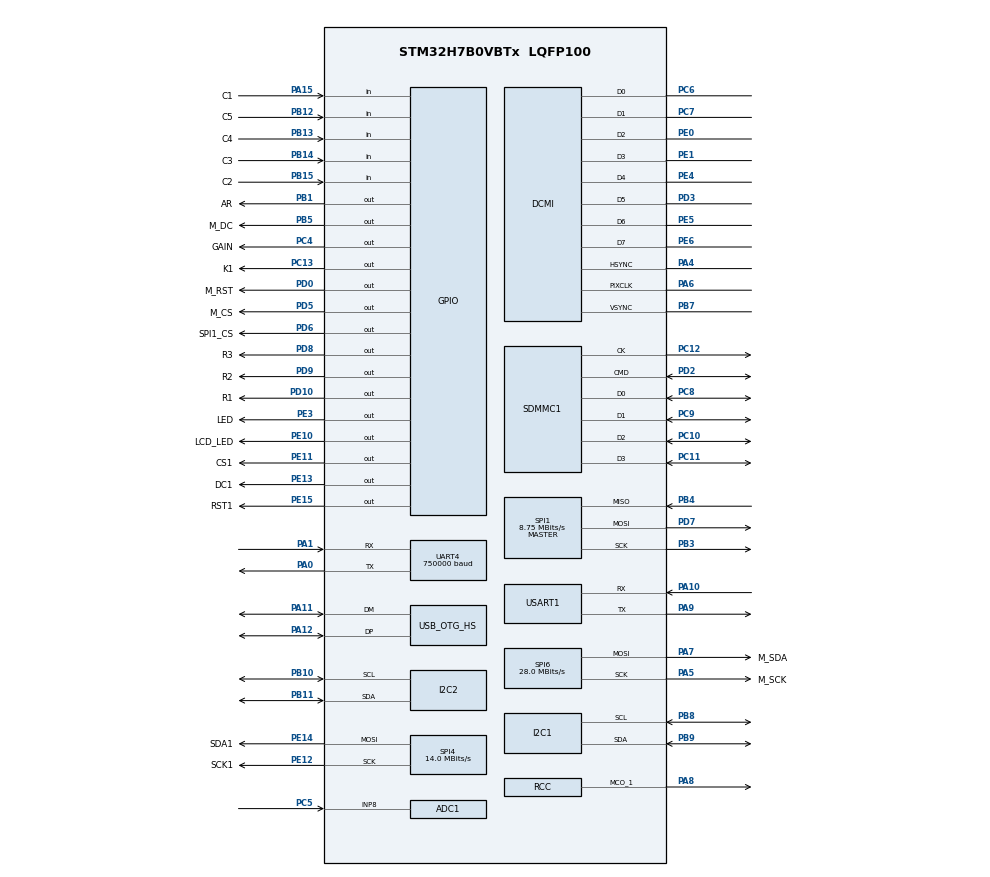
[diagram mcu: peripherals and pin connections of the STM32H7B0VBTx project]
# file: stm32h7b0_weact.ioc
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ADC1.Channel-0\#ChannelRegularConversion=ADC_CHANNEL_8
ADC1.ClockPrescaler=ADC_CLOCK_ASYNC_DIV8
ADC1.NbrOfConversionFlag=1
ADC1.OffsetNumber-0\#ChannelRegularConversion=ADC_OFFSET_NONE
ADC1.OffsetSignedSaturation-0\#ChannelRegularConversion=DISABLE
ADC1.Rank-0\#ChannelRegularConversion=1
ADC1.SamplingTime-0\#ChannelRegularConversion=ADC_SAMPLETIME_1CYCLE_5
ADC1.master=1
ADC2.Channel-0\#ChannelRegularConversion=ADC_CHANNEL_8
ADC2.ClockPrescaler=ADC_CLOCK_ASYNC_DIV8
ADC2.ContinuousConvMode=DISABLE
ADC2.ConversionDataManagement=ADC_CONVERSIONDATA_DMA_CIRCULAR
ADC2.DiscontinuousConvMode=ENABLE
ADC2.ExternalTrigConv=ADC_EXTERNALTRIG_T15_TRGO
ADC2.NbrOfConversionFlag=1
ADC2.OffsetNumber-0\#ChannelRegularConversion=ADC_OFFSET_NONE
ADC2.OffsetSignedSaturation-0\#ChannelRegularConversion=DISABLE
ADC2.Rank-0\#ChannelRegularConversion=1
ADC2.SamplingTime-0\#ChannelRegularConversion=ADC_SAMPLETIME_1CYCLE_5
CORTEX_M7.CPU_DCache=Enabled
CORTEX_M7.CPU_ICache=Enabled
Dma.ADC2.1.Direction=DMA_PERIPH_TO_MEMORY
Dma.ADC2.1.EventEnable=DISABLE
Dma.ADC2.1.FIFOMode=DMA_FIFOMODE_DISABLE
Dma.ADC2.1.Instance=DMA1_Stream0
Dma.ADC2.1.MemDataAlignment=DMA_MDATAALIGN_HALFWORD
Dma.ADC2.1.MemInc=DMA_MINC_ENABLE
Dma.ADC2.1.Mode=DMA_CIRCULAR
Dma.ADC2.1.PeriphDataAlignment=DMA_PDATAALIGN_HALFWORD
Dma.ADC2.1.PeriphInc=DMA_PINC_DISABLE
Dma.ADC2.1.Polarity=HAL_DMAMUX_REQ_GEN_RISING
Dma.ADC2.1.Priority=DMA_PRIORITY_LOW
Dma.ADC2.1.RequestNumber=1
Dma.ADC2.1.SignalID=NONE
Dma.ADC2.1.SyncEnable=DISABLE
Dma.ADC2.1.SyncPolarity=HAL_DMAMUX_SYNC_NO_EVENT
Dma.ADC2.1.SyncRequestNumber=1
Dma.ADC2.1.SyncSignalID=NONE
Dma.MEMTOMEM.2.Direction=DMA_MEMORY_TO_MEMORY
Dma.MEMTOMEM.2.EventEnable=DISABLE
Dma.MEMTOMEM.2.FIFOMode=DMA_FIFOMODE_ENABLE
Dma.MEMTOMEM.2.FIFOThreshold=DMA_FIFO_THRESHOLD_FULL
Dma.MEMTOMEM.2.Instance=DMA1_Stream1
Dma.MEMTOMEM.2.MemBurst=DMA_MBURST_SINGLE
Dma.MEMTOMEM.2.MemDataAlignment=DMA_MDATAALIGN_HALFWORD
Dma.MEMTOMEM.2.MemInc=DMA_MINC_ENABLE
Dma.MEMTOMEM.2.Mode=DMA_NORMAL
Dma.MEMTOMEM.2.PeriphBurst=DMA_PBURST_SINGLE
Dma.MEMTOMEM.2.PeriphDataAlignment=DMA_PDATAALIGN_HALFWORD
Dma.MEMTOMEM.2.PeriphInc=DMA_PINC_ENABLE
Dma.MEMTOMEM.2.Polarity=HAL_DMAMUX_REQ_GEN_RISING
Dma.MEMTOMEM.2.Priority=DMA_PRIORITY_LOW
Dma.MEMTOMEM.2.RequestNumber=1
Dma.MEMTOMEM.2.SignalID=NONE
Dma.MEMTOMEM.2.SyncEnable=DISABLE
Dma.MEMTOMEM.2.SyncPolarity=HAL_DMAMUX_SYNC_NO_EVENT
Dma.MEMTOMEM.2.SyncRequestNumber=1
Dma.MEMTOMEM.2.SyncSignalID=NONE
Dma.Request0=SPI4_TX
Dma.Request1=ADC2
Dma.Request2=MEMTOMEM
Dma.Request3=UART4_RX
Dma.Request4=UART4_TX
Dma.SPI4_TX.0.Direction=DMA_MEMORY_TO_PERIPH
Dma.SPI4_TX.0.EventEnable=DISABLE
Dma.SPI4_TX.0.FIFOMode=DMA_FIFOMODE_DISABLE
Dma.SPI4_TX.0.Instance=DMA1_Stream4
Dma.SPI4_TX.0.MemDataAlignment=DMA_MDATAALIGN_BYTE
Dma.SPI4_TX.0.MemInc=DMA_MINC_ENABLE
Dma.SPI4_TX.0.Mode=DMA_NORMAL
Dma.SPI4_TX.0.PeriphDataAlignment=DMA_PDATAALIGN_BYTE
Dma.SPI4_TX.0.PeriphInc=DMA_PINC_DISABLE
Dma.SPI4_TX.0.Polarity=HAL_DMAMUX_REQ_GEN_RISING
Dma.SPI4_TX.0.Priority=DMA_PRIORITY_LOW
Dma.SPI4_TX.0.RequestNumber=1
Dma.SPI4_TX.0.SignalID=NONE
Dma.SPI4_TX.0.SyncEnable=DISABLE
Dma.SPI4_TX.0.SyncPolarity=HAL_DMAMUX_SYNC_NO_EVENT
Dma.SPI4_TX.0.SyncRequestNumber=1
Dma.SPI4_TX.0.SyncSignalID=NONE
Dma.UART4_RX.3.Direction=DMA_PERIPH_TO_MEMORY
Dma.UART4_RX.3.EventEnable=DISABLE
Dma.UART4_RX.3.FIFOMode=DMA_FIFOMODE_DISABLE
Dma.UART4_RX.3.Instance=DMA1_Stream2
Dma.UART4_RX.3.MemDataAlignment=DMA_MDATAALIGN_BYTE
Dma.UART4_RX.3.MemInc=DMA_MINC_ENABLE
Dma.UART4_RX.3.Mode=DMA_NORMAL
Dma.UART4_RX.3.PeriphDataAlignment=DMA_PDATAALIGN_BYTE
Dma.UART4_RX.3.PeriphInc=DMA_PINC_DISABLE
Dma.UART4_RX.3.Polarity=HAL_DMAMUX_REQ_GEN_RISING
Dma.UART4_RX.3.Priority=DMA_PRIORITY_LOW
Dma.UART4_RX.3.RequestNumber=1
Dma.UART4_RX.3.SignalID=NONE
Dma.UART4_RX.3.SyncEnable=DISABLE
Dma.UART4_RX.3.SyncPolarity=HAL_DMAMUX_SYNC_NO_EVENT
Dma.UART4_RX.3.SyncRequestNumber=1
Dma.UART4_RX.3.SyncSignalID=NONE
Dma.UART4_TX.4.Direction=DMA_MEMORY_TO_PERIPH
Dma.UART4_TX.4.EventEnable=DISABLE
Dma.UART4_TX.4.FIFOMode=DMA_FIFOMODE_DISABLE
Dma.UART4_TX.4.Instance=DMA1_Stream3
Dma.UART4_TX.4.MemDataAlignment=DMA_MDATAALIGN_BYTE
Dma.UART4_TX.4.MemInc=DMA_MINC_ENABLE
Dma.UART4_TX.4.Mode=DMA_NORMAL
Dma.UART4_TX.4.PeriphDataAlignment=DMA_PDATAALIGN_BYTE
Dma.UART4_TX.4.PeriphInc=DMA_PINC_DISABLE
Dma.UART4_TX.4.Polarity=HAL_DMAMUX_REQ_GEN_RISING
Dma.UART4_TX.4.Priority=DMA_PRIORITY_LOW
Dma.UART4_TX.4.RequestNumber=1
Dma.UART4_TX.4.SignalID=NONE
Dma.UART4_TX.4.SyncEnable=DISABLE
Dma.UART4_TX.4.SyncPolarity=HAL_DMAMUX_SYNC_NO_EVENT
Dma.UART4_TX.4.SyncRequestNumber=1
Dma.UART4_TX.4.SyncSignalID=NONE
FREERTOS.HEAP_NUMBER=4
FREERTOS.Tasks01=defaultTask,24,128,StartDefaultTask,Default,NULL,Dynamic,NULL,NULL
FREERTOS.configTOTAL_HEAP_SIZE=131072
I2C1.Timing=0x20B0CCFF
I2C2.Timing=0x20B0CCFF
Mcu.Family=STM32H7
Mcu.Name=STM32H7B0VBTx
Mcu.Package=LQFP100
NVIC.ADC_IRQn=true\:5\:0\:false\:false\:true\:true\:true\:true\:true
NVIC.DMA1_Stream0_IRQn=true\:5\:0\:false\:false\:true\:true\:false\:true\:true
NVIC.DMA1_Stream2_IRQn=true\:5\:0\:false\:false\:true\:true\:false\:true\:true
NVIC.DMA1_Stream3_IRQn=true\:5\:0\:false\:false\:true\:true\:false\:true\:true
NVIC.DMA1_Stream4_IRQn=true\:6\:0\:true\:false\:true\:false\:false\:true\:true
NVIC.OTG_HS_IRQn=true\:5\:0\:false\:false\:true\:true\:true\:true\:true
NVIC.PriorityGroup=NVIC_PRIORITYGROUP_4
NVIC.SPI4_IRQn=true\:5\:0\:false\:false\:true\:true\:false\:true\:true
NVIC.TIM16_IRQn=true\:5\:0\:false\:false\:true\:true\:true\:true\:true
NVIC.TIM2_IRQn=true\:15\:0\:false\:false\:true\:false\:false\:true\:true
NVIC.TimeBase=TIM2_IRQn
NVIC.TimeBaseIP=TIM2
PA0.Mode=Asynchronous
PA0.Signal=UART4_TX
PA1.Mode=Asynchronous
PA1.Signal=UART4_RX
PA10.Mode=Asynchronous
PA10.Signal=USART1_RX
PA11.Mode=Device_Only_FS
PA11.Signal=USB_OTG_HS_DM
PA12.Mode=Device_Only_FS
PA12.Signal=USB_OTG_HS_DP
PA13.Mode=Serial_Wire
PA13.Signal=DEBUG_JTMS-SWDIO
PA14.Mode=Serial_Wire
PA14.Signal=DEBUG_JTCK-SWCLK
PA15.GPIO_Label=C1
PA15.GPIO_PuPd=GPIO_PULLDOWN
PA15.Signal=GPIO_Input
PA4.Mode=Slave_8_bits_External_Synchro
PA4.Signal=DCMI_HSYNC
PA5.GPIO_Label=M_SCK
PA5.Mode=TX_Only_Simplex_Unidirect_Master
PA5.Signal=SPI6_SCK
PA6.Mode=Slave_8_bits_External_Synchro
PA6.Signal=DCMI_PIXCLK
PA7.GPIO_Label=M_SDA
PA7.Mode=TX_Only_Simplex_Unidirect_Master
PA7.Signal=SPI6_MOSI
PA8.Mode=Clock-out-1
PA8.Signal=RCC_MCO_1
PA9.Mode=Asynchronous
PA9.Signal=USART1_TX
PB1.GPIO_Label=AR
PB1.Signal=GPIO_Output
PB10.Mode=I2C
PB10.Signal=I2C2_SCL
PB11.Mode=I2C
PB11.Signal=I2C2_SDA
PB12.GPIO_Label=C5
PB12.GPIO_PuPd=GPIO_PULLDOWN
PB12.Signal=GPIO_Input
PB13.GPIO_Label=C4
PB13.GPIO_PuPd=GPIO_PULLDOWN
PB13.Signal=GPIO_Input
PB14.GPIO_Label=C3
PB14.GPIO_PuPd=GPIO_PULLDOWN
PB14.Signal=GPIO_Input
PB15.GPIO_Label=C2
PB15.GPIO_PuPd=GPIO_PULLDOWN
PB15.Signal=GPIO_Input
PB2.Signal=OCTOSPIM_P1_CLK
PB3.Mode=Full_Duplex_Master
PB3.Signal=SPI1_SCK
PB4.Mode=Full_Duplex_Master
PB4.Signal=SPI1_MISO
PB5.GPIO_Label=M_DC
PB5.GPIO_Speed=GPIO_SPEED_FREQ_VERY_HIGH
PB5.Signal=GPIO_Output
PB6.Signal=OCTOSPIM_P1_NCS
PB7.Mode=Slave_8_bits_External_Synchro
PB7.Signal=DCMI_VSYNC
PB8.Mode=I2C
PB8.Signal=I2C1_SCL
PB9.Mode=I2C
PB9.Signal=I2C1_SDA
PC10.Mode=SD_4_bits_Wide_bus
PC10.Signal=SDMMC1_D2
PC11.Mode=SD_4_bits_Wide_bus
PC11.Signal=SDMMC1_D3
PC12.Mode=SD_4_bits_Wide_bus
PC12.Signal=SDMMC1_CK
PC13.GPIO_Label=K1
PC13.Signal=GPIO_Output
PC14-OSC32_IN.Mode=LSE-External-Oscillator
PC14-OSC32_IN.Signal=RCC_OSC32_IN
PC15-OSC32_OUT.Mode=LSE-External-Oscillator
PC15-OSC32_OUT.Signal=RCC_OSC32_OUT
PC4.GPIO_Label=GAIN
PC4.Signal=GPIO_Output
PC5.Signal=ADCx_INP8
PC6.Mode=Slave_8_bits_External_Synchro
PC6.Signal=DCMI_D0
PC7.Mode=Slave_8_bits_External_Synchro
PC7.Signal=DCMI_D1
PC8.Mode=SD_4_bits_Wide_bus
PC8.Signal=SDMMC1_D0
PC9.Mode=SD_4_bits_Wide_bus
PC9.Signal=SDMMC1_D1
PD0.GPIO_Label=M_RST
PD0.GPIO_Speed=GPIO_SPEED_FREQ_VERY_HIGH
PD0.Signal=GPIO_Output
PD10.GPIO_Label=R1
PD10.GPIO_PuPd=GPIO_NOPULL
PD10.Signal=GPIO_Output
PD11.Signal=OCTOSPIM_P1_IO0
PD12.Signal=OCTOSPIM_P1_IO1
PD13.Signal=OCTOSPIM_P1_IO3
PD2.Mode=SD_4_bits_Wide_bus
PD2.Signal=SDMMC1_CMD
PD3.Mode=Slave_8_bits_External_Synchro
PD3.Signal=DCMI_D5
PD5.GPIO_Label=M_CS
PD5.GPIO_Speed=GPIO_SPEED_FREQ_VERY_HIGH
PD5.Signal=GPIO_Output
PD6.GPIO_Label=SPI1_CS
PD6.Signal=GPIO_Output
PD7.Mode=Full_Duplex_Master
PD7.Signal=SPI1_MOSI
PD8.GPIO_Label=R3
PD8.Signal=GPIO_Output
PD9.GPIO_Label=R2
PD9.GPIO_PuPd=GPIO_NOPULL
PD9.Signal=GPIO_Output
PE0.Mode=Slave_8_bits_External_Synchro
PE0.Signal=DCMI_D2
PE1.Mode=Slave_8_bits_External_Synchro
PE1.Signal=DCMI_D3
PE10.GPIO_Label=LCD_LED
PE10.Signal=GPIO_Output
PE11.GPIO_Label=CS1
PE11.Signal=GPIO_Output
PE12.GPIO_Label=SCK1
PE12.Mode=TX_Only_Simplex_Unidirect_Master
PE12.Signal=SPI4_SCK
PE13.GPIO_Label=DC1
PE13.Signal=GPIO_Output
PE14.GPIO_Label=SDA1
PE14.Mode=TX_Only_Simplex_Unidirect_Master
PE14.Signal=SPI4_MOSI
PE15.GPIO_Label=RST1
PE15.Signal=GPIO_Output
PE2.Signal=OCTOSPIM_P1_IO2
PE3.GPIO_Label=LED
PE3.Signal=GPIO_Output
PE4.Mode=Slave_8_bits_External_Synchro
PE4.Signal=DCMI_D4
PE5.Mode=Slave_8_bits_External_Synchro
PE5.Signal=DCMI_D6
PE6.Mode=Slave_8_bits_External_Synchro
PE6.Signal=DCMI_D7
PH0-OSC_IN.Mode=HSE-External-Oscillator
PH0-OSC_IN.Signal=RCC_OSC_IN
PH1-OSC_OUT.Mode=HSE-External-Oscillator
PH1-OSC_OUT.Signal=RCC_OSC_OUT
ProjectManager.HeapSize=0x1000
ProjectManager.StackSize=0x400
ProjectManager.TargetToolchain=Makefile
RCC.ADCCLockSelection=RCC_ADCCLKSOURCE_PLL3
RCC.ADCFreq_Value=48000000
RCC.APB1Freq_Value=140000000
RCC.APB2Freq_Value=140000000
RCC.APB3Freq_Value=140000000
RCC.APB4Freq_Value=140000000
RCC.CDPPRE=RCC_APB3_DIV2
RCC.CDPPRE1=RCC_APB1_DIV2
RCC.CDPPRE2=RCC_APB2_DIV2
RCC.CortexFreq_Value=280000000
RCC.DIVM1=5
RCC.DIVM2=25
RCC.DIVM3=25
RCC.DIVN1=112
RCC.DIVN2=224
RCC.DIVN3=144
RCC.DIVQ1=4
RCC.DIVQ3=3
RCC.DIVR3=3
RCC.HCLKFreq_Value=280000000
RCC.HSE_VALUE=25000000
RCC.PLL3FRACN=0
RCC.PLLSourceVirtual=RCC_PLLSOURCE_HSE
RCC.QSPICLockSelection=RCC_OSPICLKSOURCE_PLL2
RCC.SPI6CLockSelection=RCC_SPI6CLKSOURCE_PLL2
RCC.SRDPPRE=RCC_APB4_DIV2
RCC.SYSCLKFreq_VALUE=280000000
RCC.SYSCLKSource=RCC_SYSCLKSOURCE_PLLCLK
RCC.Spi45ClockSelection=RCC_SPI45CLKSOURCE_PLL2
RCC.USART16CLockSelection=RCC_USART16910CLKSOURCE_PLL2
RCC.USBCLockSelection=RCC_USBCLKSOURCE_PLL3
RCC.USBFreq_Value=48000000
RTC.Date=23
RTC.Format=RTC_FORMAT_BIN
RTC.Hours=11
RTC.Minutes=11
RTC.Seconds=11
RTC.WeekDay=RTC_WEEKDAY_TUESDAY
SH.ADCx_INP8.0=ADC1_INP8,IN8-Single-Ended
SH.ADCx_INP8.1=ADC2_INP8,IN8-Single-Ended
SPI1.BaudRatePrescaler=SPI_BAUDRATEPRESCALER_16
SPI1.CalculateBaudRate=8.75 MBits/s
SPI1.DataSize=SPI_DATASIZE_8BIT
SPI1.Direction=SPI_DIRECTION_2LINES
SPI1.Mode=SPI_MODE_MASTER
SPI1.VirtualType=VM_MASTER
SPI4.BaudRatePrescaler=SPI_BAUDRATEPRESCALER_8
SPI4.CalculateBaudRate=14.0 MBits/s
SPI4.DataSize=SPI_DATASIZE_8BIT
SPI4.Direction=SPI_DIRECTION_2LINES_TXONLY
SPI4.Mode=SPI_MODE_MASTER
SPI4.VirtualType=VM_MASTER
SPI6.BaudRatePrescaler=SPI_BAUDRATEPRESCALER_4
SPI6.CLKPhase=SPI_PHASE_1EDGE
SPI6.CLKPolarity=SPI_POLARITY_HIGH
SPI6.CalculateBaudRate=28.0 MBits/s
SPI6.DataSize=SPI_DATASIZE_8BIT
SPI6.Direction=SPI_DIRECTION_2LINES_TXONLY
SPI6.Mode=SPI_MODE_MASTER
SPI6.VirtualType=VM_MASTER
TIM15.AutoReloadPreload=TIM_AUTORELOAD_PRELOAD_ENABLE
TIM15.Period=20
TIM15.Prescaler=279
TIM15.TIM_MasterOutputTrigger=TIM_TRGO_UPDATE
TIM16.AutoReloadPreload=TIM_AUTORELOAD_PRELOAD_ENABLE
TIM16.Period=25
TIM16.Prescaler=279
TIM17.Prescaler=279
UART4.BaudRate=750000
USART1.VirtualMode-Asynchronous=VM_ASYNC
USB_OTG_HS.VirtualMode-Device_Only_FS=Device_Only_FS
VP_FREERTOS_VS_CMSIS_V2.Mode=CMSIS_V2
VP_JPEG_VS_JPEG.Mode=JPEG_Activate
VP_LIBJPEG_VS_JPEGLIB.Mode=Enabled
VP_RNG_VS_RNG.Mode=RNG_Activate
VP_RTC_VS_RTC_Activate.Mode=RTC_Enabled
VP_RTC_VS_RTC_Calendar.Mode=RTC_Calendar
VP_SYS_VS_tim2.Mode=TIM2
VP_TIM15_VS_ClockSourceINT.Mode=Internal
VP_TIM16_VS_ClockSourceINT.Mode=Enable_Timer
VP_TIM17_VS_ClockSourceINT.Mode=Enable_Timer
board=custom

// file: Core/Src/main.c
/* USER CODE BEGIN Header */
/**
  ******************************************************************************
  * @file           : main.c
  * @brief          : Main program body
  ******************************************************************************
  * @attention
  *
  * Copyright (c) 2024 STMicroelectronics.
  * All rights reserved.
  *
  * This software is licensed under terms that can be found in the LICENSE file
  * in the root directory of this software component.
  * If no LICENSE file comes with this software, it is provided AS-IS.
  *
  ******************************************************************************
  */
/* USER CODE END Header */
#include "main.h"
#include "cmsis_os.h"

/* USER CODE BEGIN Includes */
#include "core.h"
extern void load(void);
/* USER CODE END Includes */

ADC_HandleTypeDef hadc1;
ADC_HandleTypeDef hadc2;
DMA_HandleTypeDef hdma_adc2;

DCMI_HandleTypeDef hdcmi;

I2C_HandleTypeDef hi2c1;
I2C_HandleTypeDef hi2c2;

RNG_HandleTypeDef hrng;

RTC_HandleTypeDef hrtc;

SD_HandleTypeDef hsd1;

SPI_HandleTypeDef hspi1;
SPI_HandleTypeDef hspi4;
SPI_HandleTypeDef hspi6;
DMA_HandleTypeDef hdma_spi4_tx;

TIM_HandleTypeDef htim15;
TIM_HandleTypeDef htim16;
TIM_HandleTypeDef htim17;

UART_HandleTypeDef huart4;
UART_HandleTypeDef huart1;
DMA_HandleTypeDef hdma_uart4_rx;
DMA_HandleTypeDef hdma_uart4_tx;

PCD_HandleTypeDef hpcd_USB_OTG_HS;

DMA_HandleTypeDef hdma_memtomem_dma1_stream1;
/* Definitions for defaultTask */
osThreadId_t defaultTaskHandle;
const osThreadAttr_t defaultTask_attributes = {
  .name = "defaultTask",
  .stack_size = 128 * 4,
  .priority = (osPriority_t) osPriorityNormal,
};

void SystemClock_Config(void);
void PeriphCommonClock_Config(void);
static void MX_GPIO_Init(void);
static void MX_DMA_Init(void);
static void MX_SPI4_Init(void);
static void MX_ADC1_Init(void);
static void MX_ADC2_Init(void);
static void MX_I2C2_Init(void);
static void MX_SPI6_Init(void);
static void MX_RNG_Init(void);
static void MX_USB_OTG_HS_PCD_Init(void);
static void MX_I2C1_Init(void);
static void MX_TIM17_Init(void);
static void MX_DCMI_Init(void);
static void MX_RTC_Init(void);
static void MX_TIM16_Init(void);
static void MX_TIM15_Init(void);
static void MX_SDMMC1_SD_Init(void);
static void MX_SPI1_Init(void);
static void MX_USART1_UART_Init(void);
static void MX_UART4_Init(void);
void StartDefaultTask(void *argument);

int main(void)
{

  /* Enable I-Cache---------------------------------------------------------*/
  SCB_EnableICache();

  /* Enable D-Cache---------------------------------------------------------*/
  SCB_EnableDCache();

  /* MCU Configuration--------------------------------------------------------*/

  /* Reset of all peripherals, Initializes the Flash interface and the Systick. */
  HAL_Init();

  /* Configure the system clock */
  SystemClock_Config();

/* Configure the peripherals common clocks */
  PeriphCommonClock_Config();

  /* Initialize all configured peripherals */
  MX_GPIO_Init();
  MX_DMA_Init();
  MX_SPI4_Init();
  MX_ADC1_Init();
  MX_ADC2_Init();
  MX_I2C2_Init();
  MX_SPI6_Init();
  MX_RNG_Init();
  MX_USB_OTG_HS_PCD_Init();
  MX_I2C1_Init();
  MX_TIM17_Init();
  MX_DCMI_Init();
  MX_RTC_Init();
  MX_TIM16_Init();
  MX_TIM15_Init();
  MX_SDMMC1_SD_Init();
  MX_SPI1_Init();
  MX_USART1_UART_Init();
  MX_UART4_Init();

  /* Init scheduler */
  osKernelInitialize();

  /* Create the thread(s) */
  /* creation of defaultTask */
  defaultTaskHandle = osThreadNew(StartDefaultTask, NULL, &defaultTask_attributes);

  /* USER CODE BEGIN RTOS_EVENTS */
  load();
  /* add events, ... */
  /* USER CODE END RTOS_EVENTS */

  /* Start scheduler */
  osKernelStart();
  /* We should never get here as control is now taken by the scheduler */
  /* Infinite loop */
  /* USER CODE BEGIN WHILE */
  core();
  while (1)
  {
    HAL_GPIO_TogglePin(LED_GPIO_Port, LED_Pin);
    HAL_Delay(500);
    /* USER CODE END WHILE */

  }
}

void SystemClock_Config(void)
{
  RCC_OscInitTypeDef RCC_OscInitStruct = {0};
  RCC_ClkInitTypeDef RCC_ClkInitStruct = {0};

  /*AXI clock gating */
  RCC->CKGAENR = 0xFFFFFFFF;

  /** Supply configuration update enable
  */
  HAL_PWREx_ConfigSupply(PWR_LDO_SUPPLY);

  /** Configure the main internal regulator output voltage
  */
  __HAL_PWR_VOLTAGESCALING_CONFIG(PWR_REGULATOR_VOLTAGE_SCALE0);

  while(!__HAL_PWR_GET_FLAG(PWR_FLAG_VOSRDY)) {}

  /** Initializes the RCC Oscillators according to the specified parameters
  * in the RCC_OscInitTypeDef structure.
  */
  RCC_OscInitStruct.OscillatorType = RCC_OSCILLATORTYPE_HSI48|RCC_OSCILLATORTYPE_HSI
                              |RCC_OSCILLATORTYPE_LSI|RCC_OSCILLATORTYPE_HSE;
  RCC_OscInitStruct.HSEState = RCC_HSE_ON;
  RCC_OscInitStruct.HSIState = RCC_HSI_DIV1;
  RCC_OscInitStruct.HSICalibrationValue = 64;
  RCC_OscInitStruct.LSIState = RCC_LSI_ON;
  RCC_OscInitStruct.HSI48State = RCC_HSI48_ON;
  RCC_OscInitStruct.PLL.PLLState = RCC_PLL_ON;
  RCC_OscInitStruct.PLL.PLLSource = RCC_PLLSOURCE_HSE;
  RCC_OscInitStruct.PLL.PLLM = 5;
  RCC_OscInitStruct.PLL.PLLN = 112;
  RCC_OscInitStruct.PLL.PLLP = 2;
  RCC_OscInitStruct.PLL.PLLQ = 4;
  RCC_OscInitStruct.PLL.PLLR = 2;
  RCC_OscInitStruct.PLL.PLLRGE = RCC_PLL1VCIRANGE_2;
  RCC_OscInitStruct.PLL.PLLVCOSEL = RCC_PLL1VCOWIDE;
  RCC_OscInitStruct.PLL.PLLFRACN = 0;
  if (HAL_RCC_OscConfig(&RCC_OscInitStruct) != HAL_OK)
  {
    Error_Handler();
  }

  /** Initializes the CPU, AHB and APB buses clocks
  */
  RCC_ClkInitStruct.ClockType = RCC_CLOCKTYPE_HCLK|RCC_CLOCKTYPE_SYSCLK
                              |RCC_CLOCKTYPE_PCLK1|RCC_CLOCKTYPE_PCLK2
                              |RCC_CLOCKTYPE_D3PCLK1|RCC_CLOCKTYPE_D1PCLK1;
  RCC_ClkInitStruct.SYSCLKSource = RCC_SYSCLKSOURCE_PLLCLK;
  RCC_ClkInitStruct.SYSCLKDivider = RCC_SYSCLK_DIV1;
  RCC_ClkInitStruct.AHBCLKDivider = RCC_HCLK_DIV1;
  RCC_ClkInitStruct.APB3CLKDivider = RCC_APB3_DIV2;
  RCC_ClkInitStruct.APB1CLKDivider = RCC_APB1_DIV2;
  RCC_ClkInitStruct.APB2CLKDivider = RCC_APB2_DIV2;
  RCC_ClkInitStruct.APB4CLKDivider = RCC_APB4_DIV2;

  if (HAL_RCC_ClockConfig(&RCC_ClkInitStruct, FLASH_LATENCY_7) != HAL_OK)
  {
    Error_Handler();
  }
  HAL_RCC_MCOConfig(RCC_MCO1, RCC_MCO1SOURCE_HSI, RCC_MCODIV_1);
}

void PeriphCommonClock_Config(void)
{
  RCC_PeriphCLKInitTypeDef PeriphClkInitStruct = {0};

  /** Initializes the peripherals clock
  */
  PeriphClkInitStruct.PeriphClockSelection = RCC_PERIPHCLK_USB|RCC_PERIPHCLK_SPI6
                              |RCC_PERIPHCLK_ADC|RCC_PERIPHCLK_SPI4
                              |RCC_PERIPHCLK_USART1;
  PeriphClkInitStruct.PLL2.PLL2M = 25;
  PeriphClkInitStruct.PLL2.PLL2N = 172;
  PeriphClkInitStruct.PLL2.PLL2P = 2;
  PeriphClkInitStruct.PLL2.PLL2Q = 1;
  PeriphClkInitStruct.PLL2.PLL2R = 2;
  PeriphClkInitStruct.PLL2.PLL2RGE = RCC_PLL2VCIRANGE_0;
  PeriphClkInitStruct.PLL2.PLL2VCOSEL = RCC_PLL2VCOWIDE;
  PeriphClkInitStruct.PLL2.PLL2FRACN = 0;
  PeriphClkInitStruct.PLL3.PLL3M = 25;
  PeriphClkInitStruct.PLL3.PLL3N = 144;
  PeriphClkInitStruct.PLL3.PLL3P = 2;
  PeriphClkInitStruct.PLL3.PLL3Q = 3;
  PeriphClkInitStruct.PLL3.PLL3R = 3;
  PeriphClkInitStruct.PLL3.PLL3RGE = RCC_PLL3VCIRANGE_0;
  PeriphClkInitStruct.PLL3.PLL3VCOSEL = RCC_PLL3VCOWIDE;
  PeriphClkInitStruct.PLL3.PLL3FRACN = 0;
  PeriphClkInitStruct.Spi45ClockSelection = RCC_SPI45CLKSOURCE_PLL2;
  PeriphClkInitStruct.Usart16ClockSelection = RCC_USART16910CLKSOURCE_PLL2;
  PeriphClkInitStruct.UsbClockSelection = RCC_USBCLKSOURCE_PLL3;
  PeriphClkInitStruct.AdcClockSelection = RCC_ADCCLKSOURCE_PLL3;
  PeriphClkInitStruct.Spi6ClockSelection = RCC_SPI6CLKSOURCE_PLL3;
  if (HAL_RCCEx_PeriphCLKConfig(&PeriphClkInitStruct) != HAL_OK)
  {
    Error_Handler();
  }
}

static void MX_ADC1_Init(void)
{

  ADC_MultiModeTypeDef multimode = {0};
  ADC_ChannelConfTypeDef sConfig = {0};

  /** Common config
  */
  hadc1.Instance = ADC1;
  hadc1.Init.ClockPrescaler = ADC_CLOCK_ASYNC_DIV8;
  hadc1.Init.Resolution = ADC_RESOLUTION_16B;
  hadc1.Init.ScanConvMode = ADC_SCAN_DISABLE;
  hadc1.Init.EOCSelection = ADC_EOC_SINGLE_CONV;
  hadc1.Init.LowPowerAutoWait = DISABLE;
  hadc1.Init.ContinuousConvMode = DISABLE;
  hadc1.Init.NbrOfConversion = 1;
  hadc1.Init.DiscontinuousConvMode = DISABLE;
  hadc1.Init.ExternalTrigConv = ADC_SOFTWARE_START;
  hadc1.Init.ExternalTrigConvEdge = ADC_EXTERNALTRIGCONVEDGE_NONE;
  hadc1.Init.ConversionDataManagement = ADC_CONVERSIONDATA_DR;
  hadc1.Init.Overrun = ADC_OVR_DATA_PRESERVED;
  hadc1.Init.LeftBitShift = ADC_LEFTBITSHIFT_NONE;
  hadc1.Init.OversamplingMode = DISABLE;
  if (HAL_ADC_Init(&hadc1) != HAL_OK)
  {
    Error_Handler();
  }

  /** Configure the ADC multi-mode
  */
  multimode.Mode = ADC_MODE_INDEPENDENT;
  if (HAL_ADCEx_MultiModeConfigChannel(&hadc1, &multimode) != HAL_OK)
  {
    Error_Handler();
  }

  /** Configure Regular Channel
  */
  sConfig.Channel = ADC_CHANNEL_8;
  sConfig.Rank = ADC_REGULAR_RANK_1;
  sConfig.SamplingTime = ADC_SAMPLETIME_1CYCLE_5;
  sConfig.SingleDiff = ADC_SINGLE_ENDED;
  sConfig.OffsetNumber = ADC_OFFSET_NONE;
  sConfig.Offset = 0;
  sConfig.OffsetSignedSaturation = DISABLE;
  if (HAL_ADC_ConfigChannel(&hadc1, &sConfig) != HAL_OK)
  {
    Error_Handler();
  }

}

static void MX_ADC2_Init(void)
{

  ADC_ChannelConfTypeDef sConfig = {0};

  /** Common config
  */
  hadc2.Instance = ADC2;
  hadc2.Init.ClockPrescaler = ADC_CLOCK_ASYNC_DIV8;
  hadc2.Init.Resolution = ADC_RESOLUTION_16B;
  hadc2.Init.ScanConvMode = ADC_SCAN_DISABLE;
  hadc2.Init.EOCSelection = ADC_EOC_SINGLE_CONV;
  hadc2.Init.LowPowerAutoWait = DISABLE;
  hadc2.Init.ContinuousConvMode = DISABLE;
  hadc2.Init.NbrOfConversion = 1;
  hadc2.Init.DiscontinuousConvMode = ENABLE;
  hadc2.Init.NbrOfDiscConversion = 1;
  hadc2.Init.ExternalTrigConv = ADC_EXTERNALTRIG_T15_TRGO;
  hadc2.Init.ExternalTrigConvEdge = ADC_EXTERNALTRIGCONVEDGE_RISING;
  hadc2.Init.ConversionDataManagement = ADC_CONVERSIONDATA_DMA_CIRCULAR;
  hadc2.Init.Overrun = ADC_OVR_DATA_PRESERVED;
  hadc2.Init.LeftBitShift = ADC_LEFTBITSHIFT_NONE;
  hadc2.Init.OversamplingMode = DISABLE;
  if (HAL_ADC_Init(&hadc2) != HAL_OK)
  {
    Error_Handler();
  }

  /** Configure Regular Channel
  */
  sConfig.Channel = ADC_CHANNEL_8;
  sConfig.Rank = ADC_REGULAR_RANK_1;
  sConfig.SamplingTime = ADC_SAMPLETIME_1CYCLE_5;
  sConfig.SingleDiff = ADC_SINGLE_ENDED;
  sConfig.OffsetNumber = ADC_OFFSET_NONE;
  sConfig.Offset = 0;
  sConfig.OffsetSignedSaturation = DISABLE;
  if (HAL_ADC_ConfigChannel(&hadc2, &sConfig) != HAL_OK)
  {
    Error_Handler();
  }

}

static void MX_DCMI_Init(void)
{

  hdcmi.Instance = DCMI;
  hdcmi.Init.SynchroMode = DCMI_SYNCHRO_HARDWARE;
  hdcmi.Init.PCKPolarity = DCMI_PCKPOLARITY_FALLING;
  hdcmi.Init.VSPolarity = DCMI_VSPOLARITY_LOW;
  hdcmi.Init.HSPolarity = DCMI_HSPOLARITY_LOW;
  hdcmi.Init.CaptureRate = DCMI_CR_ALL_FRAME;
  hdcmi.Init.ExtendedDataMode = DCMI_EXTEND_DATA_8B;
  hdcmi.Init.JPEGMode = DCMI_JPEG_DISABLE;
  hdcmi.Init.ByteSelectMode = DCMI_BSM_ALL;
  hdcmi.Init.ByteSelectStart = DCMI_OEBS_ODD;
  hdcmi.Init.LineSelectMode = DCMI_LSM_ALL;
  hdcmi.Init.LineSelectStart = DCMI_OELS_ODD;
  if (HAL_DCMI_Init(&hdcmi) != HAL_OK)
  {
    Error_Handler();
  }

}

static void MX_I2C1_Init(void)
{

  hi2c1.Instance = I2C1;
  hi2c1.Init.Timing = 0x20B0CCFF;
  hi2c1.Init.OwnAddress1 = 0;
  hi2c1.Init.AddressingMode = I2C_ADDRESSINGMODE_7BIT;
  hi2c1.Init.DualAddressMode = I2C_DUALADDRESS_DISABLE;
  hi2c1.Init.OwnAddress2 = 0;
  hi2c1.Init.OwnAddress2Masks = I2C_OA2_NOMASK;
  hi2c1.Init.GeneralCallMode = I2C_GENERALCALL_DISABLE;
  hi2c1.Init.NoStretchMode = I2C_NOSTRETCH_DISABLE;
  if (HAL_I2C_Init(&hi2c1) != HAL_OK)
  {
    Error_Handler();
  }

  /** Configure Analogue filter
  */
  if (HAL_I2CEx_ConfigAnalogFilter(&hi2c1, I2C_ANALOGFILTER_ENABLE) != HAL_OK)
  {
    Error_Handler();
  }

  /** Configure Digital filter
  */
  if (HAL_I2CEx_ConfigDigitalFilter(&hi2c1, 0) != HAL_OK)
  {
    Error_Handler();
  }

}

static void MX_I2C2_Init(void)
{

  hi2c2.Instance = I2C2;
  hi2c2.Init.Timing = 0x20B0CCFF;
  hi2c2.Init.OwnAddress1 = 0;
  hi2c2.Init.AddressingMode = I2C_ADDRESSINGMODE_7BIT;
  hi2c2.Init.DualAddressMode = I2C_DUALADDRESS_DISABLE;
  hi2c2.Init.OwnAddress2 = 0;
  hi2c2.Init.OwnAddress2Masks = I2C_OA2_NOMASK;
  hi2c2.Init.GeneralCallMode = I2C_GENERALCALL_DISABLE;
  hi2c2.Init.NoStretchMode = I2C_NOSTRETCH_DISABLE;
  if (HAL_I2C_Init(&hi2c2) != HAL_OK)
  {
    Error_Handler();
  }

  /** Configure Analogue filter
  */
  if (HAL_I2CEx_ConfigAnalogFilter(&hi2c2, I2C_ANALOGFILTER_ENABLE) != HAL_OK)
  {
    Error_Handler();
  }

  /** Configure Digital filter
  */
  if (HAL_I2CEx_ConfigDigitalFilter(&hi2c2, 0) != HAL_OK)
  {
    Error_Handler();
  }

}

static void MX_RNG_Init(void)
{

  hrng.Instance = RNG;
  hrng.Init.ClockErrorDetection = RNG_CED_ENABLE;
  if (HAL_RNG_Init(&hrng) != HAL_OK)
  {
    Error_Handler();
  }

}

static void MX_RTC_Init(void)
{

  RTC_TimeTypeDef sTime = {0};
  RTC_DateTypeDef sDate = {0};

  /** Initialize RTC Only
  */
  hrtc.Instance = RTC;
  hrtc.Init.HourFormat = RTC_HOURFORMAT_24;
  hrtc.Init.AsynchPrediv = 127;
  hrtc.Init.SynchPrediv = 255;
  hrtc.Init.OutPut = RTC_OUTPUT_DISABLE;
  hrtc.Init.OutPutPolarity = RTC_OUTPUT_POLARITY_HIGH;
  hrtc.Init.OutPutType = RTC_OUTPUT_TYPE_OPENDRAIN;
  hrtc.Init.OutPutRemap = RTC_OUTPUT_REMAP_NONE;
  if (HAL_RTC_Init(&hrtc) != HAL_OK)
  {
    Error_Handler();
  }

  /** Initialize RTC and set the Time and Date
  */
  sTime.Hours = 11;
  sTime.Minutes = 11;
  sTime.Seconds = 11;
  sTime.DayLightSaving = RTC_DAYLIGHTSAVING_NONE;
  sTime.StoreOperation = RTC_STOREOPERATION_RESET;
  if (HAL_RTC_SetTime(&hrtc, &sTime, RTC_FORMAT_BIN) != HAL_OK)
  {
    Error_Handler();
  }
  sDate.WeekDay = RTC_WEEKDAY_TUESDAY;
  sDate.Month = RTC_MONTH_JANUARY;
  sDate.Date = 23;
  sDate.Year = 0;

  if (HAL_RTC_SetDate(&hrtc, &sDate, RTC_FORMAT_BIN) != HAL_OK)
  {
    Error_Handler();
  }

}

static void MX_SDMMC1_SD_Init(void)
{

  hsd1.Instance = SDMMC1;
  hsd1.Init.ClockEdge = SDMMC_CLOCK_EDGE_RISING;
  hsd1.Init.ClockPowerSave = SDMMC_CLOCK_POWER_SAVE_DISABLE;
  hsd1.Init.BusWide = SDMMC_BUS_WIDE_4B;
  hsd1.Init.HardwareFlowControl = SDMMC_HARDWARE_FLOW_CONTROL_DISABLE;
  hsd1.Init.ClockDiv = 0;
  if (HAL_SD_Init(&hsd1) != HAL_OK)
  {
    Error_Handler();
  }

}

static void MX_SPI1_Init(void)
{

  /* SPI1 parameter configuration*/
  hspi1.Instance = SPI1;
  hspi1.Init.Mode = SPI_MODE_MASTER;
  hspi1.Init.Direction = SPI_DIRECTION_2LINES;
  hspi1.Init.DataSize = SPI_DATASIZE_8BIT;
  hspi1.Init.CLKPolarity = SPI_POLARITY_LOW;
  hspi1.Init.CLKPhase = SPI_PHASE_1EDGE;
  hspi1.Init.NSS = SPI_NSS_SOFT;
  hspi1.Init.BaudRatePrescaler = SPI_BAUDRATEPRESCALER_16;
  hspi1.Init.FirstBit = SPI_FIRSTBIT_MSB;
  hspi1.Init.TIMode = SPI_TIMODE_DISABLE;
  hspi1.Init.CRCCalculation = SPI_CRCCALCULATION_DISABLE;
  hspi1.Init.CRCPolynomial = 0x0;
  hspi1.Init.NSSPMode = SPI_NSS_PULSE_ENABLE;
  hspi1.Init.NSSPolarity = SPI_NSS_POLARITY_LOW;
  hspi1.Init.FifoThreshold = SPI_FIFO_THRESHOLD_01DATA;
  hspi1.Init.TxCRCInitializationPattern = SPI_CRC_INITIALIZATION_ALL_ZERO_PATTERN;
  hspi1.Init.RxCRCInitializationPattern = SPI_CRC_INITIALIZATION_ALL_ZERO_PATTERN;
  hspi1.Init.MasterSSIdleness = SPI_MASTER_SS_IDLENESS_00CYCLE;
  hspi1.Init.MasterInterDataIdleness = SPI_MASTER_INTERDATA_IDLENESS_00CYCLE;
  hspi1.Init.MasterReceiverAutoSusp = SPI_MASTER_RX_AUTOSUSP_DISABLE;
  hspi1.Init.MasterKeepIOState = SPI_MASTER_KEEP_IO_STATE_DISABLE;
  hspi1.Init.IOSwap = SPI_IO_SWAP_DISABLE;
  if (HAL_SPI_Init(&hspi1) != HAL_OK)
  {
    Error_Handler();
  }

}

static void MX_SPI4_Init(void)
{

  /* SPI4 parameter configuration*/
  hspi4.Instance = SPI4;
  hspi4.Init.Mode = SPI_MODE_MASTER;
  hspi4.Init.Direction = SPI_DIRECTION_2LINES_TXONLY;
  hspi4.Init.DataSize = SPI_DATASIZE_8BIT;
  hspi4.Init.CLKPolarity = SPI_POLARITY_LOW;
  hspi4.Init.CLKPhase = SPI_PHASE_1EDGE;
  hspi4.Init.NSS = SPI_NSS_SOFT;
  hspi4.Init.BaudRatePrescaler = SPI_BAUDRATEPRESCALER_8;
  hspi4.Init.FirstBit = SPI_FIRSTBIT_MSB;
  hspi4.Init.TIMode = SPI_TIMODE_DISABLE;
  hspi4.Init.CRCCalculation = SPI_CRCCALCULATION_DISABLE;
  hspi4.Init.CRCPolynomial = 0x0;
  hspi4.Init.NSSPMode = SPI_NSS_PULSE_ENABLE;
  hspi4.Init.NSSPolarity = SPI_NSS_POLARITY_LOW;
  hspi4.Init.FifoThreshold = SPI_FIFO_THRESHOLD_01DATA;
  hspi4.Init.TxCRCInitializationPattern = SPI_CRC_INITIALIZATION_ALL_ZERO_PATTERN;
  hspi4.Init.RxCRCInitializationPattern = SPI_CRC_INITIALIZATION_ALL_ZERO_PATTERN;
  hspi4.Init.MasterSSIdleness = SPI_MASTER_SS_IDLENESS_00CYCLE;
  hspi4.Init.MasterInterDataIdleness = SPI_MASTER_INTERDATA_IDLENESS_00CYCLE;
  hspi4.Init.MasterReceiverAutoSusp = SPI_MASTER_RX_AUTOSUSP_DISABLE;
  hspi4.Init.MasterKeepIOState = SPI_MASTER_KEEP_IO_STATE_DISABLE;
  hspi4.Init.IOSwap = SPI_IO_SWAP_DISABLE;
  if (HAL_SPI_Init(&hspi4) != HAL_OK)
  {
    Error_Handler();
  }

}

static void MX_SPI6_Init(void)
{

  /* SPI6 parameter configuration*/
  hspi6.Instance = SPI6;
  hspi6.Init.Mode = SPI_MODE_MASTER;
  hspi6.Init.Direction = SPI_DIRECTION_2LINES_TXONLY;
  hspi6.Init.DataSize = SPI_DATASIZE_8BIT;
  hspi6.Init.CLKPolarity = SPI_POLARITY_HIGH;
  hspi6.Init.CLKPhase = SPI_PHASE_1EDGE;
  hspi6.Init.NSS = SPI_NSS_SOFT;
  hspi6.Init.BaudRatePrescaler = SPI_BAUDRATEPRESCALER_2;
  hspi6.Init.FirstBit = SPI_FIRSTBIT_MSB;
  hspi6.Init.TIMode = SPI_TIMODE_DISABLE;
  hspi6.Init.CRCCalculation = SPI_CRCCALCULATION_DISABLE;
  hspi6.Init.CRCPolynomial = 0x0;
  hspi6.Init.NSSPMode = SPI_NSS_PULSE_ENABLE;
  hspi6.Init.NSSPolarity = SPI_NSS_POLARITY_LOW;
  hspi6.Init.FifoThreshold = SPI_FIFO_THRESHOLD_01DATA;
  hspi6.Init.TxCRCInitializationPattern = SPI_CRC_INITIALIZATION_ALL_ZERO_PATTERN;
  hspi6.Init.RxCRCInitializationPattern = SPI_CRC_INITIALIZATION_ALL_ZERO_PATTERN;
  hspi6.Init.MasterSSIdleness = SPI_MASTER_SS_IDLENESS_00CYCLE;
  hspi6.Init.MasterInterDataIdleness = SPI_MASTER_INTERDATA_IDLENESS_00CYCLE;
  hspi6.Init.MasterReceiverAutoSusp = SPI_MASTER_RX_AUTOSUSP_DISABLE;
  hspi6.Init.MasterKeepIOState = SPI_MASTER_KEEP_IO_STATE_DISABLE;
  hspi6.Init.IOSwap = SPI_IO_SWAP_DISABLE;
  if (HAL_SPI_Init(&hspi6) != HAL_OK)
  {
    Error_Handler();
  }

}

static void MX_TIM15_Init(void)
{

  TIM_ClockConfigTypeDef sClockSourceConfig = {0};
  TIM_MasterConfigTypeDef sMasterConfig = {0};

  htim15.Instance = TIM15;
  htim15.Init.Prescaler = 279;
  htim15.Init.CounterMode = TIM_COUNTERMODE_UP;
  htim15.Init.Period = 20;
  htim15.Init.ClockDivision = TIM_CLOCKDIVISION_DIV1;
  htim15.Init.RepetitionCounter = 0;
  htim15.Init.AutoReloadPreload = TIM_AUTORELOAD_PRELOAD_ENABLE;
  if (HAL_TIM_Base_Init(&htim15) != HAL_OK)
  {
    Error_Handler();
  }
  sClockSourceConfig.ClockSource = TIM_CLOCKSOURCE_INTERNAL;
  if (HAL_TIM_ConfigClockSource(&htim15, &sClockSourceConfig) != HAL_OK)
  {
    Error_Handler();
  }
  sMasterConfig.MasterOutputTrigger = TIM_TRGO_UPDATE;
  sMasterConfig.MasterSlaveMode = TIM_MASTERSLAVEMODE_DISABLE;
  if (HAL_TIMEx_MasterConfigSynchronization(&htim15, &sMasterConfig) != HAL_OK)
  {
    Error_Handler();
  }

}

static void MX_TIM16_Init(void)
{

  htim16.Instance = TIM16;
  htim16.Init.Prescaler = 279;
  htim16.Init.CounterMode = TIM_COUNTERMODE_UP;
  htim16.Init.Period = 25;
  htim16.Init.ClockDivision = TIM_CLOCKDIVISION_DIV1;
  htim16.Init.RepetitionCounter = 0;
  htim16.Init.AutoReloadPreload = TIM_AUTORELOAD_PRELOAD_ENABLE;
  if (HAL_TIM_Base_Init(&htim16) != HAL_OK)
  {
    Error_Handler();
  }

}

static void MX_TIM17_Init(void)
{

  htim17.Instance = TIM17;
  htim17.Init.Prescaler = 279;
  htim17.Init.CounterMode = TIM_COUNTERMODE_UP;
  htim17.Init.Period = 65535;
  htim17.Init.ClockDivision = TIM_CLOCKDIVISION_DIV1;
  htim17.Init.RepetitionCounter = 0;
  htim17.Init.AutoReloadPreload = TIM_AUTORELOAD_PRELOAD_DISABLE;
  if (HAL_TIM_Base_Init(&htim17) != HAL_OK)
  {
    Error_Handler();
  }

}

static void MX_UART4_Init(void)
{

  huart4.Instance = UART4;
  huart4.Init.BaudRate = 750000;
  huart4.Init.WordLength = UART_WORDLENGTH_8B;
  huart4.Init.StopBits = UART_STOPBITS_1;
  huart4.Init.Parity = UART_PARITY_NONE;
  huart4.Init.Mode = UART_MODE_TX_RX;
  huart4.Init.HwFlowCtl = UART_HWCONTROL_NONE;
  huart4.Init.OverSampling = UART_OVERSAMPLING_16;
  huart4.Init.OneBitSampling = UART_ONE_BIT_SAMPLE_DISABLE;
  huart4.Init.ClockPrescaler = UART_PRESCALER_DIV1;
  huart4.AdvancedInit.AdvFeatureInit = UART_ADVFEATURE_NO_INIT;
  if (HAL_UART_Init(&huart4) != HAL_OK)
  {
    Error_Handler();
  }
  if (HAL_UARTEx_SetTxFifoThreshold(&huart4, UART_TXFIFO_THRESHOLD_1_8) != HAL_OK)
  {
    Error_Handler();
  }
  if (HAL_UARTEx_SetRxFifoThreshold(&huart4, UART_RXFIFO_THRESHOLD_1_8) != HAL_OK)
  {
    Error_Handler();
  }
  if (HAL_UARTEx_DisableFifoMode(&huart4) != HAL_OK)
  {
    Error_Handler();
  }

}

static void MX_USART1_UART_Init(void)
{

  huart1.Instance = USART1;
  huart1.Init.BaudRate = 115200;
  huart1.Init.WordLength = UART_WORDLENGTH_8B;
  huart1.Init.StopBits = UART_STOPBITS_1;
  huart1.Init.Parity = UART_PARITY_NONE;
  huart1.Init.Mode = UART_MODE_TX_RX;
  huart1.Init.HwFlowCtl = UART_HWCONTROL_NONE;
  huart1.Init.OverSampling = UART_OVERSAMPLING_16;
  huart1.Init.OneBitSampling = UART_ONE_BIT_SAMPLE_DISABLE;
  huart1.Init.ClockPrescaler = UART_PRESCALER_DIV1;
  huart1.AdvancedInit.AdvFeatureInit = UART_ADVFEATURE_NO_INIT;
  if (HAL_UART_Init(&huart1) != HAL_OK)
  {
    Error_Handler();
  }
  if (HAL_UARTEx_SetTxFifoThreshold(&huart1, UART_TXFIFO_THRESHOLD_1_8) != HAL_OK)
  {
    Error_Handler();
  }
  if (HAL_UARTEx_SetRxFifoThreshold(&huart1, UART_RXFIFO_THRESHOLD_1_8) != HAL_OK)
  {
    Error_Handler();
  }
  if (HAL_UARTEx_DisableFifoMode(&huart1) != HAL_OK)
  {
    Error_Handler();
  }

}

static void MX_USB_OTG_HS_PCD_Init(void)
{

  hpcd_USB_OTG_HS.Instance = USB_OTG_HS;
  hpcd_USB_OTG_HS.Init.dev_endpoints = 9;
  hpcd_USB_OTG_HS.Init.speed = PCD_SPEED_FULL;
  hpcd_USB_OTG_HS.Init.dma_enable = DISABLE;
  hpcd_USB_OTG_HS.Init.phy_itface = USB_OTG_EMBEDDED_PHY;
  hpcd_USB_OTG_HS.Init.Sof_enable = DISABLE;
  hpcd_USB_OTG_HS.Init.low_power_enable = DISABLE;
  hpcd_USB_OTG_HS.Init.lpm_enable = DISABLE;
  hpcd_USB_OTG_HS.Init.vbus_sensing_enable = DISABLE;
  hpcd_USB_OTG_HS.Init.use_dedicated_ep1 = DISABLE;
  hpcd_USB_OTG_HS.Init.use_external_vbus = DISABLE;
  if (HAL_PCD_Init(&hpcd_USB_OTG_HS) != HAL_OK)
  {
    Error_Handler();
  }

}

static void MX_DMA_Init(void)
{

  /* DMA controller clock enable */
  __HAL_RCC_DMA1_CLK_ENABLE();

  /* Configure DMA request hdma_memtomem_dma1_stream1 on DMA1_Stream1 */
  hdma_memtomem_dma1_stream1.Instance = DMA1_Stream1;
  hdma_memtomem_dma1_stream1.Init.Request = DMA_REQUEST_MEM2MEM;
  hdma_memtomem_dma1_stream1.Init.Direction = DMA_MEMORY_TO_MEMORY;
  hdma_memtomem_dma1_stream1.Init.PeriphInc = DMA_PINC_ENABLE;
  hdma_memtomem_dma1_stream1.Init.MemInc = DMA_MINC_ENABLE;
  hdma_memtomem_dma1_stream1.Init.PeriphDataAlignment = DMA_PDATAALIGN_HALFWORD;
  hdma_memtomem_dma1_stream1.Init.MemDataAlignment = DMA_MDATAALIGN_HALFWORD;
  hdma_memtomem_dma1_stream1.Init.Mode = DMA_NORMAL;
  hdma_memtomem_dma1_stream1.Init.Priority = DMA_PRIORITY_LOW;
  hdma_memtomem_dma1_stream1.Init.FIFOMode = DMA_FIFOMODE_ENABLE;
  hdma_memtomem_dma1_stream1.Init.FIFOThreshold = DMA_FIFO_THRESHOLD_FULL;
  hdma_memtomem_dma1_stream1.Init.MemBurst = DMA_MBURST_SINGLE;
  hdma_memtomem_dma1_stream1.Init.PeriphBurst = DMA_PBURST_SINGLE;
  if (HAL_DMA_Init(&hdma_memtomem_dma1_stream1) != HAL_OK)
  {
    Error_Handler( );
  }

  /* DMA interrupt init */
  /* DMA1_Stream0_IRQn interrupt configuration */
  HAL_NVIC_SetPriority(DMA1_Stream0_IRQn, 5, 0);
  HAL_NVIC_EnableIRQ(DMA1_Stream0_IRQn);
  /* DMA1_Stream2_IRQn interrupt configuration */
  HAL_NVIC_SetPriority(DMA1_Stream2_IRQn, 5, 0);
  HAL_NVIC_EnableIRQ(DMA1_Stream2_IRQn);
  /* DMA1_Stream3_IRQn interrupt configuration */
  HAL_NVIC_SetPriority(DMA1_Stream3_IRQn, 5, 0);
  HAL_NVIC_EnableIRQ(DMA1_Stream3_IRQn);
  /* DMA1_Stream4_IRQn interrupt configuration */
  HAL_NVIC_SetPriority(DMA1_Stream4_IRQn, 6, 0);
  HAL_NVIC_EnableIRQ(DMA1_Stream4_IRQn);

}

static void MX_GPIO_Init(void)
{
  GPIO_InitTypeDef GPIO_InitStruct = {0};

  /* GPIO Ports Clock Enable */
  __HAL_RCC_GPIOE_CLK_ENABLE();
  __HAL_RCC_GPIOC_CLK_ENABLE();
  __HAL_RCC_GPIOH_CLK_ENABLE();
  __HAL_RCC_GPIOA_CLK_ENABLE();
  __HAL_RCC_GPIOB_CLK_ENABLE();
  __HAL_RCC_GPIOD_CLK_ENABLE();

  /*Configure GPIO pin Output Level */
  HAL_GPIO_WritePin(GPIOE, LED_Pin|LCD_LED_Pin|CS1_Pin|DC1_Pin
                          |RST1_Pin, GPIO_PIN_RESET);

  /*Configure GPIO pin Output Level */
  HAL_GPIO_WritePin(GPIOC, K1_Pin|GAIN_Pin, GPIO_PIN_RESET);

  /*Configure GPIO pin Output Level */
  HAL_GPIO_WritePin(GPIOB, AR_Pin|M_DC_Pin, GPIO_PIN_RESET);

  /*Configure GPIO pin Output Level */
  HAL_GPIO_WritePin(GPIOD, R3_Pin|R2_Pin|R1_Pin|M_RST_Pin
                          |M_CS_Pin|SPI1_CS_Pin, GPIO_PIN_RESET);

  /*Configure GPIO pin : PE2 */
  GPIO_InitStruct.Pin = GPIO_PIN_2;
  GPIO_InitStruct.Mode = GPIO_MODE_AF_PP;
  GPIO_InitStruct.Pull = GPIO_NOPULL;
  GPIO_InitStruct.Speed = GPIO_SPEED_FREQ_VERY_HIGH;
  GPIO_InitStruct.Alternate = GPIO_AF9_OCTOSPIM_P1;
  HAL_GPIO_Init(GPIOE, &GPIO_InitStruct);

  /*Configure GPIO pins : LED_Pin LCD_LED_Pin CS1_Pin DC1_Pin
                           RST1_Pin */
  GPIO_InitStruct.Pin = LED_Pin|LCD_LED_Pin|CS1_Pin|DC1_Pin
                          |RST1_Pin;
  GPIO_InitStruct.Mode = GPIO_MODE_OUTPUT_PP;
  GPIO_InitStruct.Pull = GPIO_NOPULL;
  GPIO_InitStruct.Speed = GPIO_SPEED_FREQ_LOW;
  HAL_GPIO_Init(GPIOE, &GPIO_InitStruct);

  /*Configure GPIO pins : K1_Pin GAIN_Pin */
  GPIO_InitStruct.Pin = K1_Pin|GAIN_Pin;
  GPIO_InitStruct.Mode = GPIO_MODE_OUTPUT_PP;
  GPIO_InitStruct.Pull = GPIO_NOPULL;
  GPIO_InitStruct.Speed = GPIO_SPEED_FREQ_LOW;
  HAL_GPIO_Init(GPIOC, &GPIO_InitStruct);

  /*Configure GPIO pin : AR_Pin */
  GPIO_InitStruct.Pin = AR_Pin;
  GPIO_InitStruct.Mode = GPIO_MODE_OUTPUT_PP;
  GPIO_InitStruct.Pull = GPIO_NOPULL;
  GPIO_InitStruct.Speed = GPIO_SPEED_FREQ_LOW;
  HAL_GPIO_Init(AR_GPIO_Port, &GPIO_InitStruct);

  /*Configure GPIO pin : PB2 */
  GPIO_InitStruct.Pin = GPIO_PIN_2;
  GPIO_InitStruct.Mode = GPIO_MODE_AF_PP;
  GPIO_InitStruct.Pull = GPIO_NOPULL;
  GPIO_InitStruct.Speed = GPIO_SPEED_FREQ_VERY_HIGH;
  GPIO_InitStruct.Alternate = GPIO_AF9_OCTOSPIM_P1;
  HAL_GPIO_Init(GPIOB, &GPIO_InitStruct);

  /*Configure GPIO pins : C5_Pin C4_Pin C3_Pin C2_Pin */
  GPIO_InitStruct.Pin = C5_Pin|C4_Pin|C3_Pin|C2_Pin;
  GPIO_InitStruct.Mode = GPIO_MODE_INPUT;
  GPIO_InitStruct.Pull = GPIO_PULLDOWN;
  HAL_GPIO_Init(GPIOB, &GPIO_InitStruct);

  /*Configure GPIO pins : R3_Pin R2_Pin R1_Pin SPI1_CS_Pin */
  GPIO_InitStruct.Pin = R3_Pin|R2_Pin|R1_Pin|SPI1_CS_Pin;
  GPIO_InitStruct.Mode = GPIO_MODE_OUTPUT_PP;
  GPIO_InitStruct.Pull = GPIO_NOPULL;
  GPIO_InitStruct.Speed = GPIO_SPEED_FREQ_LOW;
  HAL_GPIO_Init(GPIOD, &GPIO_InitStruct);

  /*Configure GPIO pins : PD11 PD12 PD13 */
  GPIO_InitStruct.Pin = GPIO_PIN_11|GPIO_PIN_12|GPIO_PIN_13;
  GPIO_InitStruct.Mode = GPIO_MODE_AF_PP;
  GPIO_InitStruct.Pull = GPIO_NOPULL;
  GPIO_InitStruct.Speed = GPIO_SPEED_FREQ_VERY_HIGH;
  GPIO_InitStruct.Alternate = GPIO_AF9_OCTOSPIM_P1;
  HAL_GPIO_Init(GPIOD, &GPIO_InitStruct);

  /*Configure GPIO pin : PA8 */
  GPIO_InitStruct.Pin = GPIO_PIN_8;
  GPIO_InitStruct.Mode = GPIO_MODE_AF_PP;
  GPIO_InitStruct.Pull = GPIO_NOPULL;
  GPIO_InitStruct.Speed = GPIO_SPEED_FREQ_LOW;
  GPIO_InitStruct.Alternate = GPIO_AF0_MCO;
  HAL_GPIO_Init(GPIOA, &GPIO_InitStruct);

  /*Configure GPIO pin : C1_Pin */
  GPIO_InitStruct.Pin = C1_Pin;
  GPIO_InitStruct.Mode = GPIO_MODE_INPUT;
  GPIO_InitStruct.Pull = GPIO_PULLDOWN;
  HAL_GPIO_Init(C1_GPIO_Port, &GPIO_InitStruct);

  /*Configure GPIO pins : M_RST_Pin M_CS_Pin */
  GPIO_InitStruct.Pin = M_RST_Pin|M_CS_Pin;
  GPIO_InitStruct.Mode = GPIO_MODE_OUTPUT_PP;
  GPIO_InitStruct.Pull = GPIO_NOPULL;
  GPIO_InitStruct.Speed = GPIO_SPEED_FREQ_VERY_HIGH;
  HAL_GPIO_Init(GPIOD, &GPIO_InitStruct);

  /*Configure GPIO pin : M_DC_Pin */
  GPIO_InitStruct.Pin = M_DC_Pin;
  GPIO_InitStruct.Mode = GPIO_MODE_OUTPUT_PP;
  GPIO_InitStruct.Pull = GPIO_NOPULL;
  GPIO_InitStruct.Speed = GPIO_SPEED_FREQ_VERY_HIGH;
  HAL_GPIO_Init(M_DC_GPIO_Port, &GPIO_InitStruct);

  /*Configure GPIO pin : PB6 */
  GPIO_InitStruct.Pin = GPIO_PIN_6;
  GPIO_InitStruct.Mode = GPIO_MODE_AF_PP;
  GPIO_InitStruct.Pull = GPIO_NOPULL;
  GPIO_InitStruct.Speed = GPIO_SPEED_FREQ_VERY_HIGH;
  GPIO_InitStruct.Alternate = GPIO_AF10_OCTOSPIM_P1;
  HAL_GPIO_Init(GPIOB, &GPIO_InitStruct);

}

void StartDefaultTask(void *argument)
{
  for(;;)
  {
    osDelay(1);
  }
}

void HAL_TIM_PeriodElapsedCallback(TIM_HandleTypeDef *htim)
{
  /* USER CODE BEGIN Callback 0 */
  // extern void my_HAL_TIM_PeriodElapsedCallback(TIM_HandleTypeDef *htim);
  // my_HAL_TIM_PeriodElapsedCallback(htim);
  /* USER CODE END Callback 0 */
  if (htim->Instance == TIM2) {
    HAL_IncTick();
  }
}

void Error_Handler(void)
{
  __disable_irq();
  while (1)
  {
  }
}
